# N32G033 register map
Vendor: Nsingtech Ltd.; File version: 1.0
Registers are 32-bit, read-write, reset 0x0 unless marked. A register's access mark holds for its fields unless they carry their own. Offsets are from the block's base; [hi:lo] are bit positions; {n}, {i} and the like mark numbered series.

## EXTI
Base 0x40010400
0x00 EXTI_EMASK — nan
  [10:0] EMASKx
0x04 EXTI_IMASK — nan
  [10:0] IMASKx
0x08 EXTI_FT_CFG — nan
  [10:0] FT_CFGx
0x0C EXTI_RT_CFG — nan
  [10:0] RT_CFGx
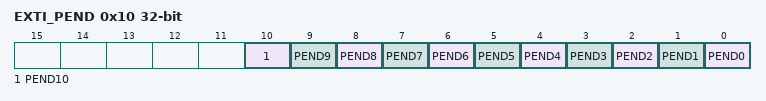
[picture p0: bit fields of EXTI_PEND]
0x10 EXTI_PEND — nan
  [n] PEND{n} (n=0..10)
0x14 EXTI_SWIE — nan
  [10:0] SWIEx

## FLASH — interal FLASH controller
Base 0x40022000
0x00 FLASH_AC reset 0x30 — nan
  [2:0] LATENCY
0x04 FLASH_KEY — nan
  [31:0] FKEY
0x08 FLASH_OPTKEY — nan
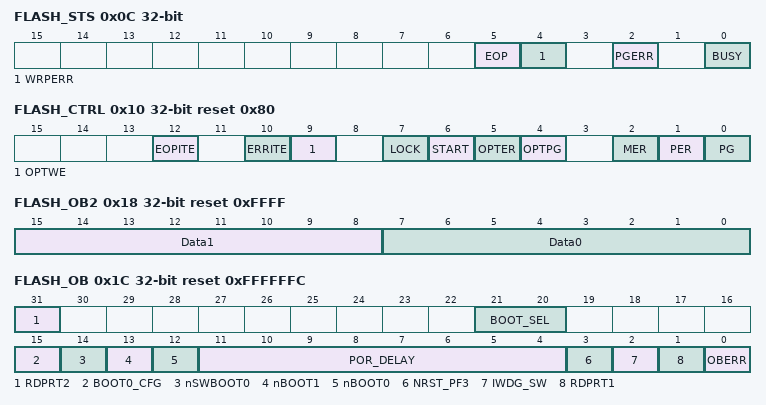
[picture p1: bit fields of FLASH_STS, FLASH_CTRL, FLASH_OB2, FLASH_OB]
0x0C FLASH_STS — nan
  [5] EOP, [4] WRPERR, [2] PGERR, [0] BUSY
0x10 FLASH_CTRL reset 0x80 — nan
  [12] EOPITE, [10] ERRITE, [9] OPTWE, [7] LOCK, [6] START, [5] OPTER, [4] OPTPG, [2] MER, [1] PER, [0] PG
0x14 FLASH_ADD — nan
  [31:0] FADD
0x18 FLASH_OB2 reset 0xFFFF — nan
  [15:8] Data1, [7:0] Data0
0x1C FLASH_OB reset 0xFFFFFFC — nan
  [31] RDPRT2, [21:20] BOOT_SEL, [15] BOOT0_CFG, [14] nSWBOOT0, [13] nBOOT1, [12] nBOOT0, [11:4] POR_DELAY, [3] NRST_PF3, [2] IWDG_SW, [1] RDPRT1, [0] OBERR
0x20 FLASH_WRP reset 0xFFFF — nan
  [15:0] WRPT
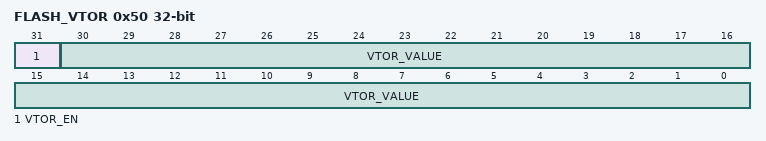
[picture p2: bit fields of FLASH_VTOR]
0x50 FLASH_VTOR — nan
  [31] VTOR_EN, [30:0] VTOR_VALUE

## GPIO
Base 0x40023000
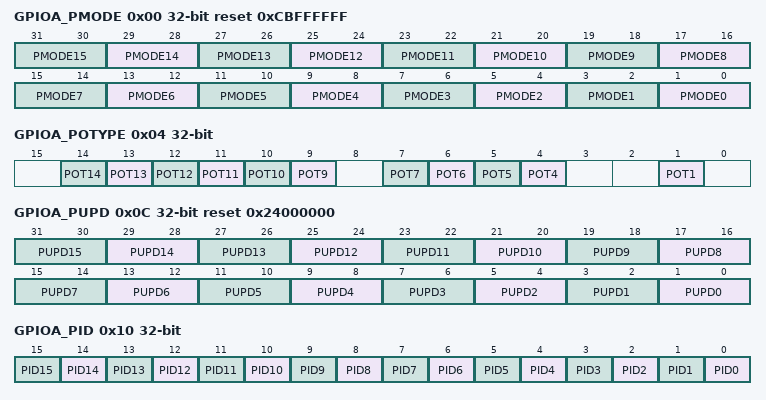
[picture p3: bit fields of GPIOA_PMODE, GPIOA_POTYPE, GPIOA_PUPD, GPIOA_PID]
0x00 GPIOA_PMODE reset 0xCBFFFFFF — GPIO mode description register
  [2n+1:2n] PMODE{n} (n=0..15)
0x04 GPIOA_POTYPE — GPIO type defenition
  [n] POT{n} (n=9..14), [n] POT{n} (n=4..7), [1] POT1
0x0C GPIOA_PUPD reset 0x24000000 — GPIO pull up pull down description register
  [2n+1:2n] PUPD{n} (n=0..15)
0x10 GPIOA_PID — GPIO input data register
  [n] PID{n} (n=0..15)
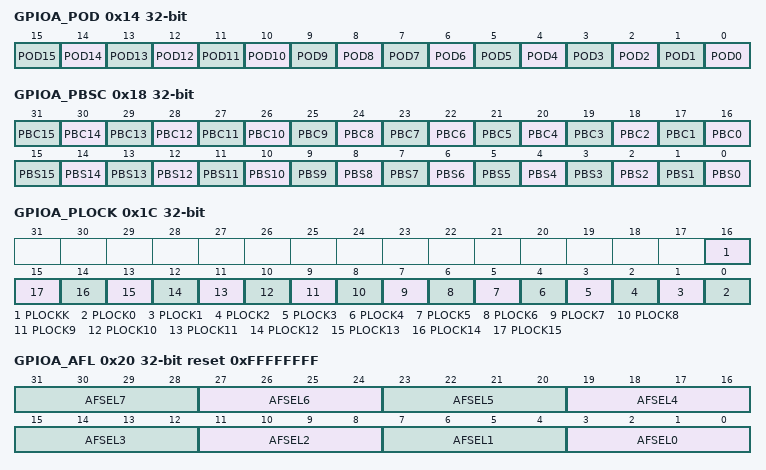
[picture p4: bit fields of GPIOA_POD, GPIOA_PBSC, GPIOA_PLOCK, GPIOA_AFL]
0x14 GPIOA_POD — GPIO output data register
  [n] POD{n} (n=0..15)
0x18 GPIOA_PBSC — PortA bit set/reset register
  [n+16] PBC{n} (n=0..15), [n] PBS{n} (n=0..15)
0x1C GPIOA_PLOCK — PortA configuration lock register
  [16] PLOCKK, [n] PLOCK{n} (n=0..15)
0x20 GPIOA_AFL reset 0xFFFFFFFF — PortA Alternate function low register
  [4n+3:4n] AFSEL{n} (n=0..7)
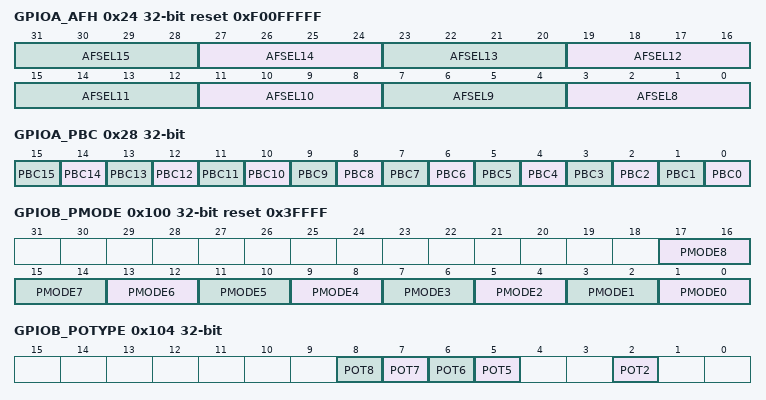
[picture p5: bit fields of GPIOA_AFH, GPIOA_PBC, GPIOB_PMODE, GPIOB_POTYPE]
0x24 GPIOA_AFH reset 0xF00FFFFF — PortA Alternate function High register
  [4n-29:4n-32] AFSEL{n} (n=8..15)
0x28 GPIOA_PBC — PortA bit reset register
  [n] PBC{n} (n=0..15)
0x100 GPIOB_PMODE reset 0x3FFFF — GPIO mode description register
  [2n+1:2n] PMODE{n} (n=0..8)
0x104 GPIOB_POTYPE — GPIO type defenition
  [n] POT{n} (n=5..8), [2] POT2
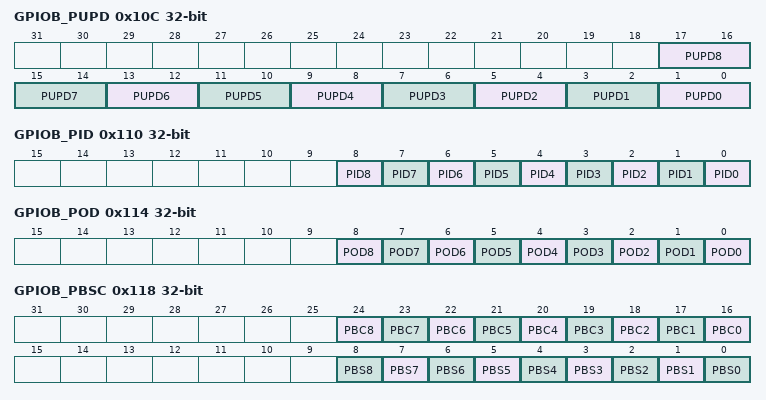
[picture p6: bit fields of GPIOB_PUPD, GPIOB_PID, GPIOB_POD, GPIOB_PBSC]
0x10C GPIOB_PUPD — GPIO pull up pull down description register
  [2n+1:2n] PUPD{n} (n=0..8)
0x110 GPIOB_PID — GPIO input data register
  [n] PID{n} (n=0..8)
0x114 GPIOB_POD — GPIO output data register
  [n] POD{n} (n=0..8)
0x118 GPIOB_PBSC — PortB bit set/reset register
  [n+16] PBC{n} (n=0..8), [n] PBS{n} (n=0..8)
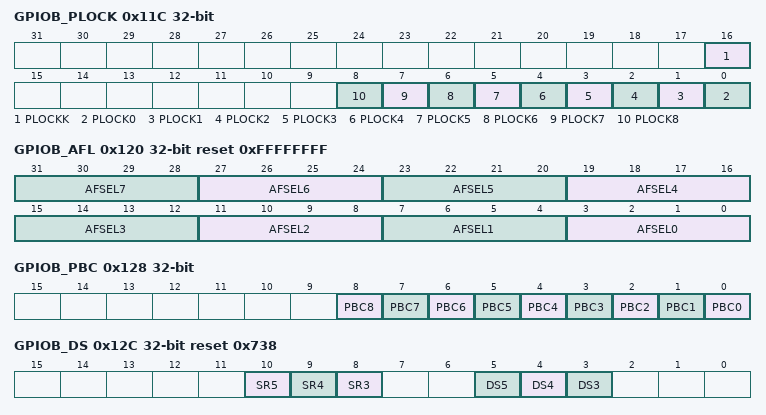
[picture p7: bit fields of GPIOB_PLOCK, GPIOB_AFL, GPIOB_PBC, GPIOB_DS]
0x11C GPIOB_PLOCK — PortB configuration lock register
  [16] PLOCKK, [n] PLOCK{n} (n=0..8)
0x120 GPIOB_AFL reset 0xFFFFFFFF — PortB Alternate function low register
  [4n+3:4n] AFSEL{n} (n=0..7)
0x124 GPIOB_AFH reset 0xF — PortB Alternate function High register
  [3:0] AFSEL8
0x128 GPIOB_PBC — PortB bit reset register
  [n] PBC{n} (n=0..8)
0x12C GPIOB_DS reset 0x738 — PortB driver strength config register
  [10] SR5, [9] SR4, [8] SR3, [5] DS5, [4] DS4, [3] DS3
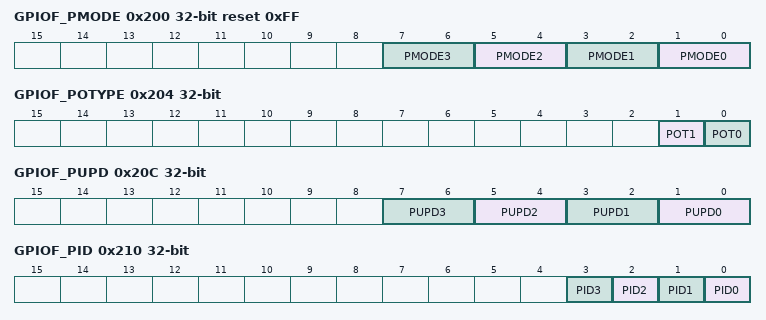
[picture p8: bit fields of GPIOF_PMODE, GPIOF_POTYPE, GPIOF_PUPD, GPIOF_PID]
0x200 GPIOF_PMODE reset 0xFF — GPIO mode description register
  [2n+1:2n] PMODE{n} (n=0..3)
0x204 GPIOF_POTYPE — GPIO type defenition
  [1] POT1, [0] POT0
0x20C GPIOF_PUPD — GPIO pull up pull down description register
  [2n+1:2n] PUPD{n} (n=0..3)
0x210 GPIOF_PID — GPIO input data register
  [n] PID{n} (n=0..3)
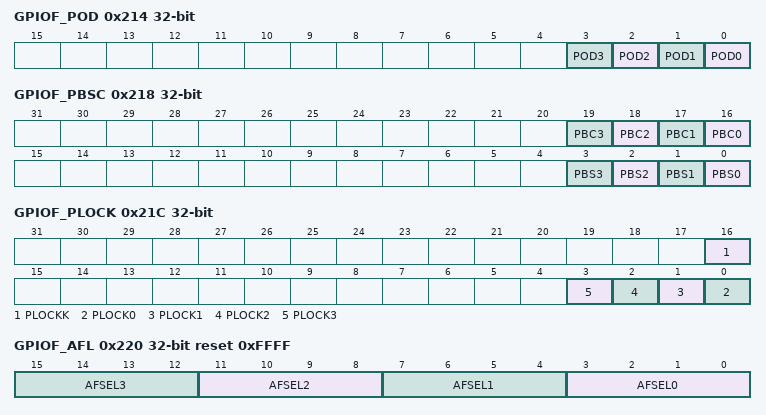
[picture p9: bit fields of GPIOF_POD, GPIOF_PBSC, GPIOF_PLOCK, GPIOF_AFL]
0x214 GPIOF_POD — GPIO output data register
  [n] POD{n} (n=0..3)
0x218 GPIOF_PBSC — PortF bit set/reset register
  [n+16] PBC{n} (n=0..3), [n] PBS{n} (n=0..3)
0x21C GPIOF_PLOCK — PortF configuration lock register
  [16] PLOCKK, [n] PLOCK{n} (n=0..3)
0x220 GPIOF_AFL reset 0xFFFF — PortF Alternate function low register
  [4n+3:4n] AFSEL{n} (n=0..3)
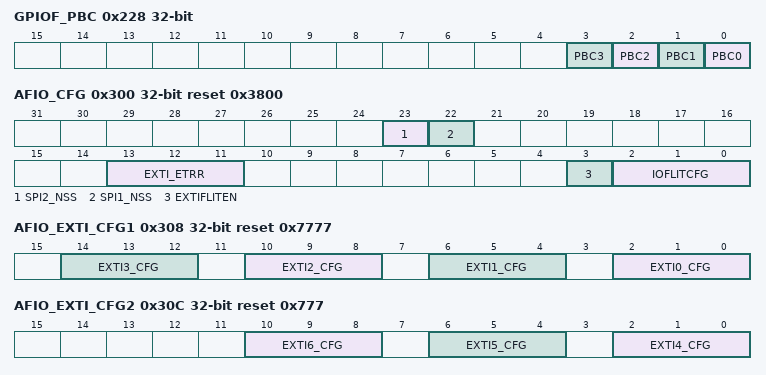
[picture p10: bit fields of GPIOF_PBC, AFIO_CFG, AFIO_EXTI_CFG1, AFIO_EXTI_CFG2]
0x228 GPIOF_PBC — PortF bit reset register
  [n] PBC{n} (n=0..3)
0x300 AFIO_CFG reset 0x3800 — Mapping configurations
  [23] SPI2_NSS, [22] SPI1_NSS, [13:11] EXTI_ETRR, [3] EXTIFLITEN, [2:0] IOFLITCFG
0x308 AFIO_EXTI_CFG1 reset 0x7777 — EXTI line configuration (0-3)
  [4n+2:4n] EXTI{n}_CFG (n=0..3)
0x30C AFIO_EXTI_CFG2 reset 0x777 — EXTI line configuration (4-7)
  [10:8] EXTI6_CFG, [6:4] EXTI5_CFG, [2:0] EXTI4_CFG
0x310 AFIO_DIGEFT_CFG1 — GPIO type defenition
  [15:0] PAyDIGEFTEN
0x314 AFIO_DIGEFT_CFG2 — GPIO type defenition
  [8:0] PByDIGEFTEN
0x318 AFIO_DIGEFT_CFG3 — GPIO type defenition
  [3:0] PFyDIGEFTEN
